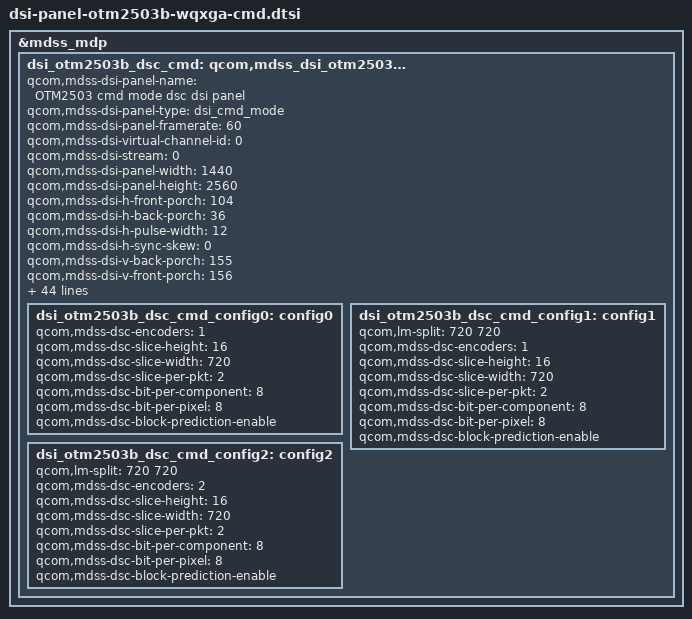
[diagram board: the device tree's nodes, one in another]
/*
 * Copyright (c) 2017, The LineageOS Project. All rights reserved.
 *
 * This program is free software; you can redistribute it and/or modify
 * it under the terms of the GNU General Public License version 2 and
 * only version 2 as published by the Free Software Foundation.
 *
 * This program is distributed in the hope that it will be useful,
 * but WITHOUT ANY WARRANTY; without even the implied warranty of
 * MERCHANTABILITY or FITNESS FOR A PARTICULAR PURPOSE.  See the
 * GNU General Public License for more details.
 *
 */

&mdss_mdp {
	dsi_otm2503b_dsc_cmd: qcom,mdss_dsi_otm2503b_dsc_wqxga_cmd {
		qcom,mdss-dsi-panel-name = "OTM2503 cmd mode dsc dsi panel";
		qcom,mdss-dsi-panel-type = "dsi_cmd_mode";
		qcom,mdss-dsi-panel-framerate = <60>;
		qcom,mdss-dsi-virtual-channel-id = <0>;
		qcom,mdss-dsi-stream = <0>;
		qcom,mdss-dsi-panel-width = <1440>;
		qcom,mdss-dsi-panel-height = <2560>;
		qcom,mdss-dsi-h-front-porch = <104>;
		qcom,mdss-dsi-h-back-porch = <36>;
		qcom,mdss-dsi-h-pulse-width = <12>;
		qcom,mdss-dsi-h-sync-skew = <0>;
		qcom,mdss-dsi-v-back-porch = <155>;
		qcom,mdss-dsi-v-front-porch = <156>;
		qcom,mdss-dsi-v-pulse-width = <1>;
		qcom,mdss-dsi-bpp = <24>;
		qcom,mdss-dsi-border-color = <0>;
		qcom,mdss-dsi-on-command-state = "dsi_lp_mode";
		qcom,mdss-dsi-off-command-state = "dsi_hs_mode";
		qcom,mdss-dsi-h-sync-pulse = <0>;
		qcom,mdss-dsi-traffic-mode = "non_burst_sync_event";
		qcom,mdss-dsi-bllp-eof-power-mode;
		qcom,mdss-dsi-bllp-power-mode;
		qcom,mdss-dsi-lane-0-state;
		qcom,mdss-dsi-lane-1-state;
		qcom,mdss-dsi-lane-2-state;
		qcom,mdss-dsi-lane-3-state;
		qcom,mdss-dsi-panel-timings = [00 13 05 04 08 0e 04 05 04 03 04 00];
		qcom,mdss-dsi-t-clk-post = <0x6>;
		qcom,mdss-dsi-t-clk-pre = <0x1f>;
		qcom,mdss-dsi-dma-trigger = "trigger_sw";
		qcom,mdss-dsi-mdp-trigger = "none";
		qcom,mdss-dsi-reset-sequence = <1 04>, <0 02>, <1 20>;
		qcom,mdss-dsi-te-pin-select = <1>;
		qcom,mdss-dsi-wr-mem-start = <0x2c>;
		qcom,mdss-dsi-wr-mem-continue = <0x3c>;
		qcom,mdss-dsi-te-dcs-command = <1>;
		qcom,mdss-dsi-te-check-enable;
		qcom,mdss-dsi-te-using-te-pin;
		qcom,ulps-enabled;
                qcom,mdss-pan-physical-width-dimension = <66>;
                qcom,mdss-pan-physical-height-dimension = <129>;

		qcom,adjust-timer-wakeup-ms = <1>;
		qcom,mdss-dsi-on-command = [
			29 01 00 00 00 00 02 00 00
			29 01 00 00 00 00 04 ff 25 03 01
			29 01 00 00 00 00 02 00 80
			29 01 00 00 00 00 03 ff 25 03
			29 01 00 00 00 00 02 00 00
			29 01 00 00 00 00 02 1c 01
			29 01 00 00 00 00 02 00 b1
			29 01 00 00 00 00 02 b0 01
			29 01 00 00 00 00 02 00 8e
			29 01 00 00 00 00 03 c0 19 05
			29 01 00 00 00 00 02 00 9e
			29 01 00 00 00 00 03 c0 19 05
			29 01 00 00 00 00 02 00 ae
			29 01 00 00 00 00 03 c0 19 05
			29 01 00 00 00 00 02 00 be
			29 01 00 00 00 00 02 b4 05
			15 01 00 00 00 00 02 35 00
			05 01 00 00 78 00 01 11
			05 01 00 00 78 00 01 29];

		qcom,mdss-dsi-post-panel-on-command = [05 01 00 00 a0 00 01 29];

		qcom,mdss-dsi-off-command = [05 01 00 00 0a 00 02 28 00
				 05 01 00 00 50 00 02 10 00];

		qcom,compression-mode = "dsc";
		qcom,config-select = <&dsi_otm2503b_dsc_cmd_config2>;

		dsi_otm2503b_dsc_cmd_config0: config0 {
			qcom,mdss-dsc-encoders = <1>;
			qcom,mdss-dsc-slice-height = <16>;
			qcom,mdss-dsc-slice-width = <720>;
			qcom,mdss-dsc-slice-per-pkt = <2>;

			qcom,mdss-dsc-bit-per-component = <8>;
			qcom,mdss-dsc-bit-per-pixel = <8>;
			qcom,mdss-dsc-block-prediction-enable;
		};

		dsi_otm2503b_dsc_cmd_config1: config1 {
			qcom,lm-split = <720 720>;
			qcom,mdss-dsc-encoders = <1>; /* 3D Mux */
			qcom,mdss-dsc-slice-height = <16>;
			qcom,mdss-dsc-slice-width = <720>;
			qcom,mdss-dsc-slice-per-pkt = <2>;

			qcom,mdss-dsc-bit-per-component = <8>;
			qcom,mdss-dsc-bit-per-pixel = <8>;
			qcom,mdss-dsc-block-prediction-enable;
		};

		dsi_otm2503b_dsc_cmd_config2: config2 {
			qcom,lm-split = <720 720>;
			qcom,mdss-dsc-encoders = <2>; /* DSC Merge */
			qcom,mdss-dsc-slice-height = <16>;
			qcom,mdss-dsc-slice-width = <720>;
			qcom,mdss-dsc-slice-per-pkt = <2>;

			qcom,mdss-dsc-bit-per-component = <8>;
			qcom,mdss-dsc-bit-per-pixel = <8>;
			qcom,mdss-dsc-block-prediction-enable;
		};
	};
};

&dsi_otm2503b_dsc_cmd {
	qcom,mdss-dsi-panel-timings = [00 13 05 04 08 0e 04 05 04 03 04 00];
	qcom,mdss-dsi-t-clk-post = <0x06>;
	qcom,mdss-dsi-t-clk-pre = <0x1f>;
	qcom,mdss-dsi-bl-min-level = <1>;
	qcom,mdss-dsi-bl-max-level = <4095>;
	qcom,panel-supply-entries = <&dsi_panel_pwr_supply_jdi>;
};
